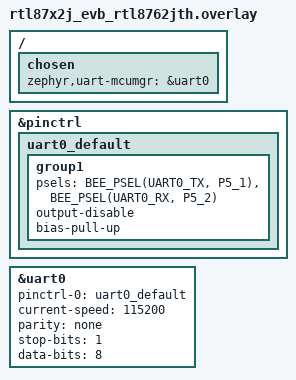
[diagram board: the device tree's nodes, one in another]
/*
 * Copyright(c) 2026, Realtek Semiconductor Corporation
 * SPDX-License-Identifier: Apache-2.0
 */

#include <dt-bindings/pinctrl/rtl87x2j-pinctrl.h>

&pinctrl {
	uart0_default: uart0_default {
		group1 {
			psels = <BEE_PSEL(UART0_TX, P5_1)>,
				<BEE_PSEL(UART0_RX, P5_2)>;
			output-disable;
			bias-pull-up;
		};
	};
};

/ {
	chosen {
		zephyr,uart-mcumgr = &uart0;
	};
};

&uart0 {
	pinctrl-0 = <&uart0_default>;
	pinctrl-names = "default";
	status = "okay";
	current-speed = <115200>;
	parity = "none";
	stop-bits = "1";
	data-bits = <8>;
};
